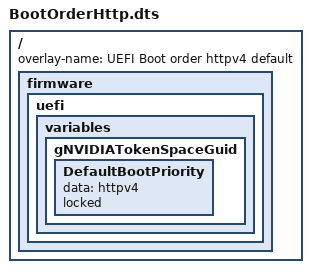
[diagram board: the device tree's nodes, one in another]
/** @file
*
*  Copyright (c) 2022, NVIDIA CORPORATION & AFFILIATES. All rights reserved.
*
*  SPDX-License-Identifier: BSD-2-Clause-Patent
*
**/

/dts-v1/;
/plugin/;

/ {
	overlay-name = "UEFI Boot order httpv4 default";

	fragment@0 {
		target-path = "/";
		board_config {
			sw-modules = "uefi";
		};

		__overlay__ {
			firmware {
				uefi {
					variables {
						gNVIDIATokenSpaceGuid {
							DefaultBootPriority {
								data = "httpv4";
								locked;
							};
						};
					};
				};
			};
		};
	};
};
